VERSION ""

NS_ :

BS_:

BU_:

BO_ 1829 CAR_EGO_SD: 8 Vector__XXX
 SG_ EGO_D : 39|32@0- (0.01,0) [-4|4] "" Vector__XXX
 SG_ EGO_S : 7|32@0+ (0.1,0) [0|5000] "" Vector__XXX

BO_ 1828 CAR_EGO_B: 8 Vector__XXX
 SG_ WAYPOINT : 39|32@0+ (1,0) [0|4294967295] "" Vector__XXX
 SG_ YAW : 7|32@0- (0.001,0) [-3.142|3.142] "" Vector__XXX

BO_ 1827 CAR_EGO_A: 8 Vector__XXX
 SG_ Y : 39|32@0+ (0.01,0) [0|1000000] "" Vector__XXX
 SG_ X : 7|32@0+ (0.01,0) [0|1000000] "" Vector__XXX

BO_ 1792 OBJ_INFO: 8 Vector__XXX
 SG_ OBJ_BOOL : 7|8@0+ (1,0) [0|1] "" Vector__XXX
 SG_ NUM_OBJ : 15|8@0+ (1,0) [0|20] "" Vector__XXX

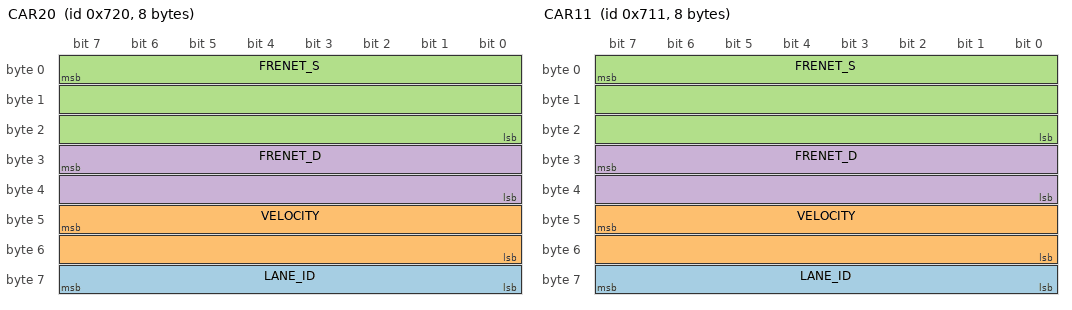
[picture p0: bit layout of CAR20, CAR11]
BO_ 1824 CAR20: 8 Vector__XXX
 SG_ LANE_ID : 63|8@0- (1,0) [-4|10] "" Vector__XXX
 SG_ VELOCITY : 47|16@0+ (0.01,0) [0|36.3] "" Vector__XXX
 SG_ FRENET_S : 7|24@0- (0.1,0) [-750|5000] "" Vector__XXX
 SG_ FRENET_D : 31|16@0- (0.01,0) [-2|2] "" Vector__XXX

BO_ 1809 CAR11: 8 Vector__XXX
 SG_ LANE_ID : 63|8@0- (1,0) [-4|10] "" Vector__XXX
 SG_ VELOCITY : 47|16@0+ (0.01,0) [0|36.3] "" Vector__XXX
 SG_ FRENET_S : 7|24@0- (0.1,0) [-750|5000] "" Vector__XXX
 SG_ FRENET_D : 31|16@0- (0.01,0) [-2|2] "" Vector__XXX

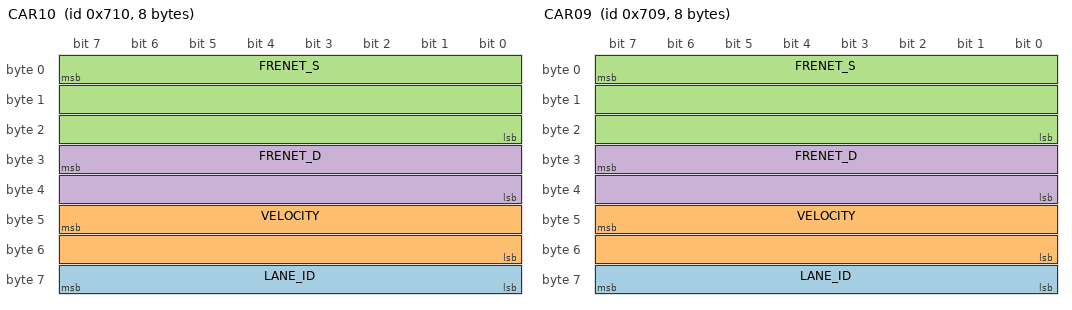
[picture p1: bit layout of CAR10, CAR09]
BO_ 1808 CAR10: 8 Vector__XXX
 SG_ LANE_ID : 63|8@0- (1,0) [-4|10] "" Vector__XXX
 SG_ VELOCITY : 47|16@0+ (0.01,0) [0|36.3] "" Vector__XXX
 SG_ FRENET_S : 7|24@0- (0.1,0) [-750|5000] "" Vector__XXX
 SG_ FRENET_D : 31|16@0- (0.01,0) [-2|2] "" Vector__XXX

BO_ 1801 CAR09: 8 Vector__XXX
 SG_ LANE_ID : 63|8@0- (1,0) [-4|10] "" Vector__XXX
 SG_ VELOCITY : 47|16@0+ (0.01,0) [0|36.3] "" Vector__XXX
 SG_ FRENET_S : 7|24@0- (0.1,0) [-750|5000] "" Vector__XXX
 SG_ FRENET_D : 31|16@0- (0.01,0) [-2|2] "" Vector__XXX

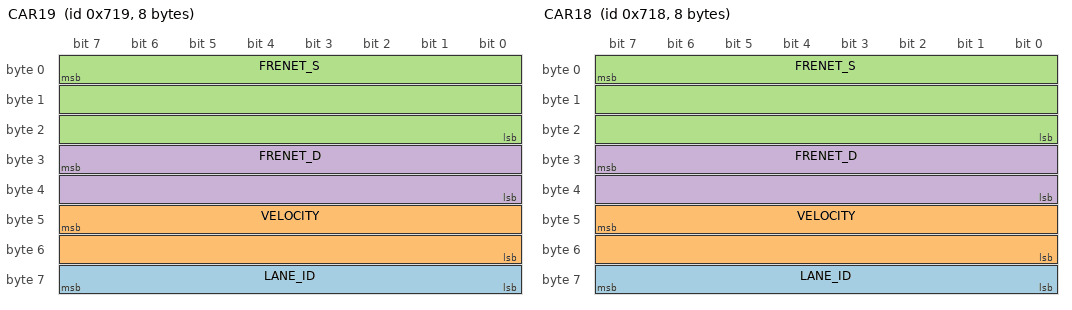
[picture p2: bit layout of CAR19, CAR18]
BO_ 1817 CAR19: 8 Vector__XXX
 SG_ LANE_ID : 63|8@0- (1,0) [-4|10] "" Vector__XXX
 SG_ VELOCITY : 47|16@0+ (0.01,0) [0|36.3] "" Vector__XXX
 SG_ FRENET_S : 7|24@0- (0.1,0) [-750|5000] "" Vector__XXX
 SG_ FRENET_D : 31|16@0- (0.01,0) [-2|2] "" Vector__XXX

BO_ 1816 CAR18: 8 Vector__XXX
 SG_ LANE_ID : 63|8@0- (1,0) [-4|10] "" Vector__XXX
 SG_ VELOCITY : 47|16@0+ (0.01,0) [0|36.3] "" Vector__XXX
 SG_ FRENET_S : 7|24@0- (0.1,0) [-750|5000] "" Vector__XXX
 SG_ FRENET_D : 31|16@0- (0.01,0) [-2|2] "" Vector__XXX

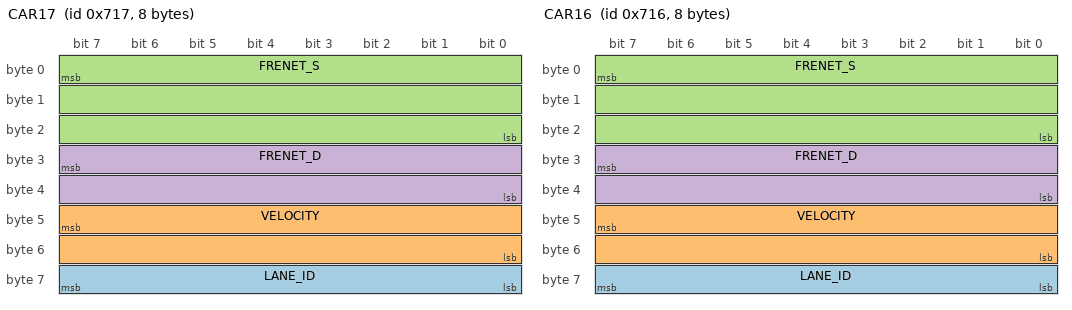
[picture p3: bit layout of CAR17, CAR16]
BO_ 1815 CAR17: 8 Vector__XXX
 SG_ LANE_ID : 63|8@0- (1,0) [-4|10] "" Vector__XXX
 SG_ VELOCITY : 47|16@0+ (0.01,0) [0|36.3] "" Vector__XXX
 SG_ FRENET_S : 7|24@0- (0.1,0) [-750|5000] "" Vector__XXX
 SG_ FRENET_D : 31|16@0- (0.01,0) [-2|2] "" Vector__XXX

BO_ 1814 CAR16: 8 Vector__XXX
 SG_ LANE_ID : 63|8@0- (1,0) [-4|10] "" Vector__XXX
 SG_ VELOCITY : 47|16@0+ (0.01,0) [0|36.3] "" Vector__XXX
 SG_ FRENET_S : 7|24@0- (0.1,0) [-750|5000] "" Vector__XXX
 SG_ FRENET_D : 31|16@0- (0.01,0) [-2|2] "" Vector__XXX

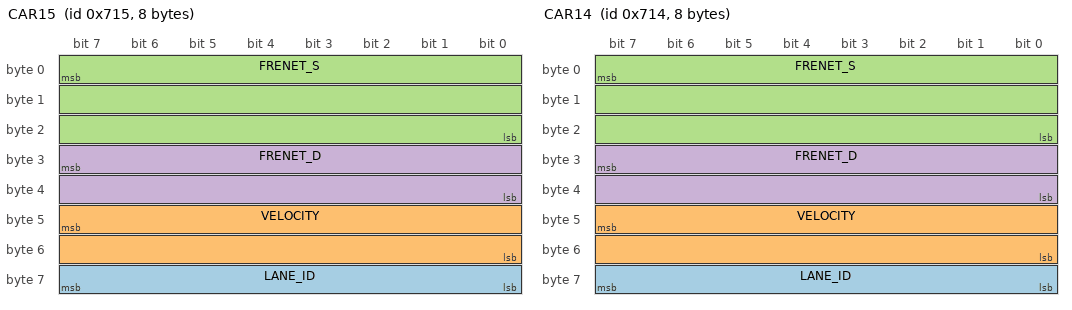
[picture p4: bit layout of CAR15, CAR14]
BO_ 1813 CAR15: 8 Vector__XXX
 SG_ LANE_ID : 63|8@0- (1,0) [-4|10] "" Vector__XXX
 SG_ VELOCITY : 47|16@0+ (0.01,0) [0|36.3] "" Vector__XXX
 SG_ FRENET_S : 7|24@0- (0.1,0) [-750|5000] "" Vector__XXX
 SG_ FRENET_D : 31|16@0- (0.01,0) [-2|2] "" Vector__XXX

BO_ 1812 CAR14: 8 Vector__XXX
 SG_ LANE_ID : 63|8@0- (1,0) [-4|10] "" Vector__XXX
 SG_ VELOCITY : 47|16@0+ (0.01,0) [0|36.3] "" Vector__XXX
 SG_ FRENET_S : 7|24@0- (0.1,0) [-750|5000] "" Vector__XXX
 SG_ FRENET_D : 31|16@0- (0.01,0) [-2|2] "" Vector__XXX

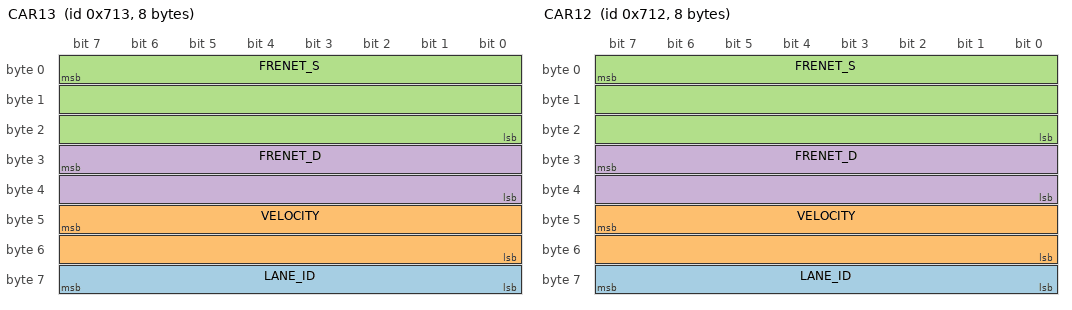
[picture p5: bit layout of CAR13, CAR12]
BO_ 1811 CAR13: 8 Vector__XXX
 SG_ LANE_ID : 63|8@0- (1,0) [-4|10] "" Vector__XXX
 SG_ VELOCITY : 47|16@0+ (0.01,0) [0|36.3] "" Vector__XXX
 SG_ FRENET_S : 7|24@0- (0.1,0) [-750|5000] "" Vector__XXX
 SG_ FRENET_D : 31|16@0- (0.01,0) [-2|2] "" Vector__XXX

BO_ 1810 CAR12: 8 Vector__XXX
 SG_ LANE_ID : 63|8@0- (1,0) [-4|10] "" Vector__XXX
 SG_ VELOCITY : 47|16@0+ (0.01,0) [0|36.3] "" Vector__XXX
 SG_ FRENET_S : 7|24@0- (0.1,0) [-750|5000] "" Vector__XXX
 SG_ FRENET_D : 31|16@0- (0.01,0) [-2|2] "" Vector__XXX

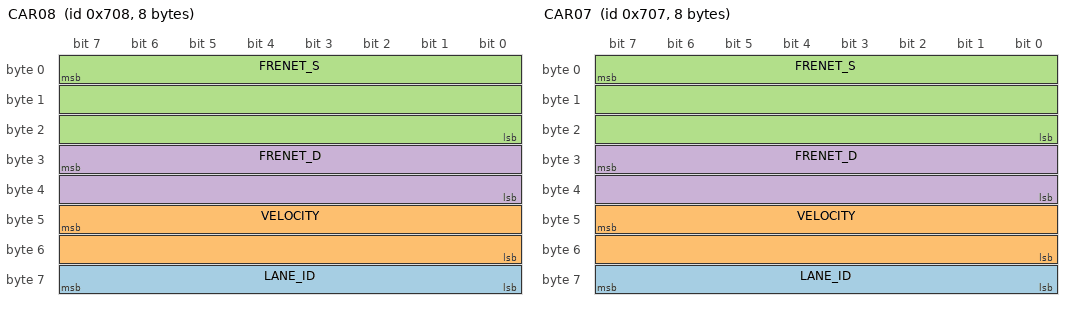
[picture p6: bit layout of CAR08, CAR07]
BO_ 1800 CAR08: 8 Vector__XXX
 SG_ LANE_ID : 63|8@0- (1,0) [-4|10] "" Vector__XXX
 SG_ VELOCITY : 47|16@0+ (0.01,0) [0|36.3] "" Vector__XXX
 SG_ FRENET_S : 7|24@0- (0.1,0) [-750|5000] "" Vector__XXX
 SG_ FRENET_D : 31|16@0- (0.01,0) [-2|2] "" Vector__XXX

BO_ 1799 CAR07: 8 Vector__XXX
 SG_ LANE_ID : 63|8@0- (1,0) [-4|10] "" Vector__XXX
 SG_ VELOCITY : 47|16@0+ (0.01,0) [0|36.3] "" Vector__XXX
 SG_ FRENET_S : 7|24@0- (0.1,0) [-750|5000] "" Vector__XXX
 SG_ FRENET_D : 31|16@0- (0.01,0) [-2|2] "" Vector__XXX

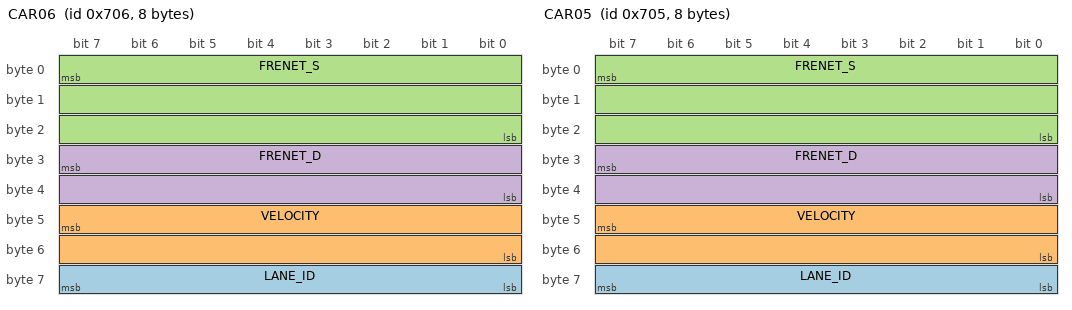
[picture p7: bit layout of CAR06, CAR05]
BO_ 1798 CAR06: 8 Vector__XXX
 SG_ LANE_ID : 63|8@0- (1,0) [-4|10] "" Vector__XXX
 SG_ VELOCITY : 47|16@0+ (0.01,0) [0|36.3] "" Vector__XXX
 SG_ FRENET_S : 7|24@0- (0.1,0) [-750|5000] "" Vector__XXX
 SG_ FRENET_D : 31|16@0- (0.01,0) [-2|2] "" Vector__XXX

BO_ 1797 CAR05: 8 Vector__XXX
 SG_ LANE_ID : 63|8@0- (1,0) [-4|10] "" Vector__XXX
 SG_ VELOCITY : 47|16@0+ (0.01,0) [0|36.3] "" Vector__XXX
 SG_ FRENET_S : 7|24@0- (0.1,0) [-750|5000] "" Vector__XXX
 SG_ FRENET_D : 31|16@0- (0.01,0) [-2|2] "" Vector__XXX

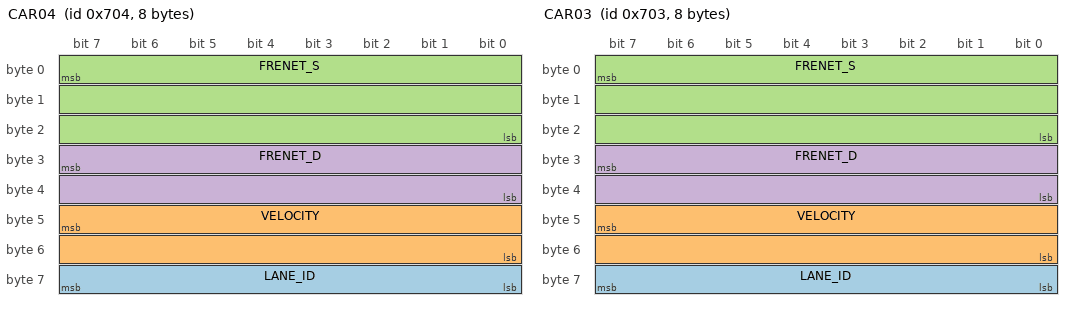
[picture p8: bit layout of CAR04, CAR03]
BO_ 1796 CAR04: 8 Vector__XXX
 SG_ LANE_ID : 63|8@0- (1,0) [-4|10] "" Vector__XXX
 SG_ VELOCITY : 47|16@0+ (0.01,0) [0|36.3] "" Vector__XXX
 SG_ FRENET_S : 7|24@0- (0.1,0) [-750|5000] "" Vector__XXX
 SG_ FRENET_D : 31|16@0- (0.01,0) [-2|2] "" Vector__XXX

BO_ 1795 CAR03: 8 Vector__XXX
 SG_ LANE_ID : 63|8@0- (1,0) [-4|10] "" Vector__XXX
 SG_ VELOCITY : 47|16@0+ (0.01,0) [0|36.3] "" Vector__XXX
 SG_ FRENET_S : 7|24@0- (0.1,0) [-750|5000] "" Vector__XXX
 SG_ FRENET_D : 31|16@0- (0.01,0) [-2|2] "" Vector__XXX

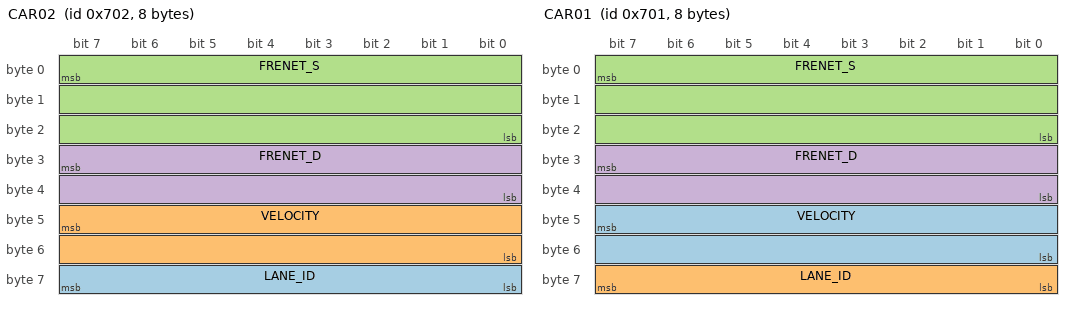
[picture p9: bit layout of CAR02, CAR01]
BO_ 1794 CAR02: 8 Vector__XXX
 SG_ LANE_ID : 63|8@0- (1,0) [-4|10] "" Vector__XXX
 SG_ VELOCITY : 47|16@0+ (0.01,0) [0|36.3] "" Vector__XXX
 SG_ FRENET_S : 7|24@0- (0.1,0) [-750|5000] "" Vector__XXX
 SG_ FRENET_D : 31|16@0- (0.01,0) [-2|2] "" Vector__XXX

BO_ 1793 CAR01: 8 Vector__XXX
 SG_ VELOCITY : 47|16@0+ (0.01,0) [0|36.3] "" Vector__XXX
 SG_ LANE_ID : 63|8@0- (1,0) [-4|10] "" Vector__XXX
 SG_ FRENET_S : 7|24@0- (0.1,0) [-750|5000] "" Vector__XXX
 SG_ FRENET_D : 31|16@0- (0.01,0) [-2|2] "" Vector__XXX

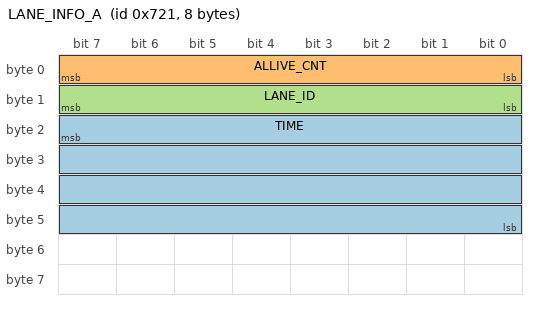
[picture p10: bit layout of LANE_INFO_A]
BO_ 1825 LANE_INFO_A: 8 Vector__XXX
 SG_ TIME : 23|32@0+ (0.1,0) [0|429496729.5] "" Vector__XXX
 SG_ ALLIVE_CNT : 7|8@0+ (1,0) [0|255] "" Vector__XXX
 SG_ LANE_ID : 15|8@0- (1,0) [-4|10] "" Vector__XXX

BO_ 1826 LANE_INFO_B: 8 Vector__XXX
 SG_ M_EXIT : 39|32@0- (0.1,0) [-214748364.8|214748364.7] "" Vector__XXX
 SG_ M_ENTER : 7|32@0- (0.1,0) [-214748364.8|214748364.7] "" Vector__XXX

BA_DEF_ SG_  "GenSigSendType" ENUM  "Cyclic","OnWrite","OnWriteWithRepetition","OnChange","OnChangeWithRepetition","IfActive","IfActiveWithRepetition","NoSigSendType";
BA_DEF_ BO_  "GenMsgCycleTime" INT 0 0;
BA_DEF_ BO_  "GenMsgSendType" ENUM  "Cyclic","not_used","not_used","not_used","not_used","Cyclic","not_used","IfActive","NoMsgSendType";
BA_DEF_  "DBName" STRING ;
BA_DEF_  "BusType" STRING ;
BA_DEF_DEF_  "GenSigSendType" "Cyclic";
BA_DEF_DEF_  "GenMsgCycleTime" 0;
BA_DEF_DEF_  "GenMsgSendType" "NoMsgSendType";
BA_DEF_DEF_  "DBName" "";
BA_DEF_DEF_  "BusType" "CAN";
BA_ "DBName" "Lane_info";
